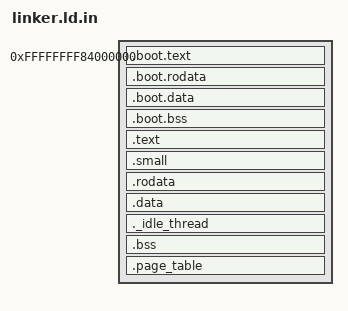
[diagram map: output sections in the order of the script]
ENTRY(_start)
       
PROVIDE(KERNEL_OFFSET = 0xFFFFFFFF00000000);
PROVIDE(START_ADDR = 0xFFFFFFFF84000000);
SECTIONS
{
    . = START_ADDR;
    .boot.text . : AT(ADDR(.boot.text) - KERNEL_OFFSET)
    {
        *(.boot.text)
    }
    .boot.rodata . : AT(ADDR(.boot.rodata) - KERNEL_OFFSET)
    {
        *(.boot.rodata)
    }
    .boot.data . : AT(ADDR(.boot.data) - KERNEL_OFFSET)
    {
        *(.boot.data)
    }
    .boot.bss . : AT(ADDR(.boot.bss) - KERNEL_OFFSET)
    {
        *(.boot.bss)
    }
    . = ALIGN(4K);
    ki_boot_end = .;
    .text . : AT(ADDR(.text) - KERNEL_OFFSET)
    {
        . = ALIGN(4K);
        /* Standard kernel */
        *(.text)
        *(.text.*)
    }
    /* Start of data section */
    _sdata = .;
    .small : {
        /* Small data that should be accessed relative to gp.  ld has trouble
           with the relaxation if they are not in a single section. */
        __global_pointer$ = . + 0x800;
        *(.srodata*)
        *(.sdata*)
        *(.sbss)
    }
    .rodata . : AT(ADDR(.rodata) - KERNEL_OFFSET)
    {
        *(.rodata)
        *(.rodata.*)
    }
    .data . : AT(ADDR(.data) - KERNEL_OFFSET)
    {
        *(.data)
        *(.data.*)
    }
    /* The kernel's idle thread section contains no code or data. */
    ._idle_thread . (NOLOAD): AT(ADDR(._idle_thread) - KERNEL_OFFSET)
    {
        *(._idle_thread)
    }
    . = ALIGN(4K);
    .bss . (NOLOAD): AT(ADDR(.bss) - KERNEL_OFFSET)
    {
        *(.bss)
        *(COMMON) /* fallback in case '-fno-common' is not used */
        /* 4k breakpoint stack */
        _breakpoint_stack_bottom = .;
        . = . + 4K;
        _breakpoint_stack_top = .;
        /* large data such as the globals frame and global PD */
        *(.bss.*)
    }
    . = ALIGN(4K);
    . = . + 8K;
    . = ALIGN(4K);
   .page_table :
    {
        . = ALIGN(4K);
        *(.page_table.aligned)
    }
    . = ALIGN(4K);
    ki_end = .;
}
